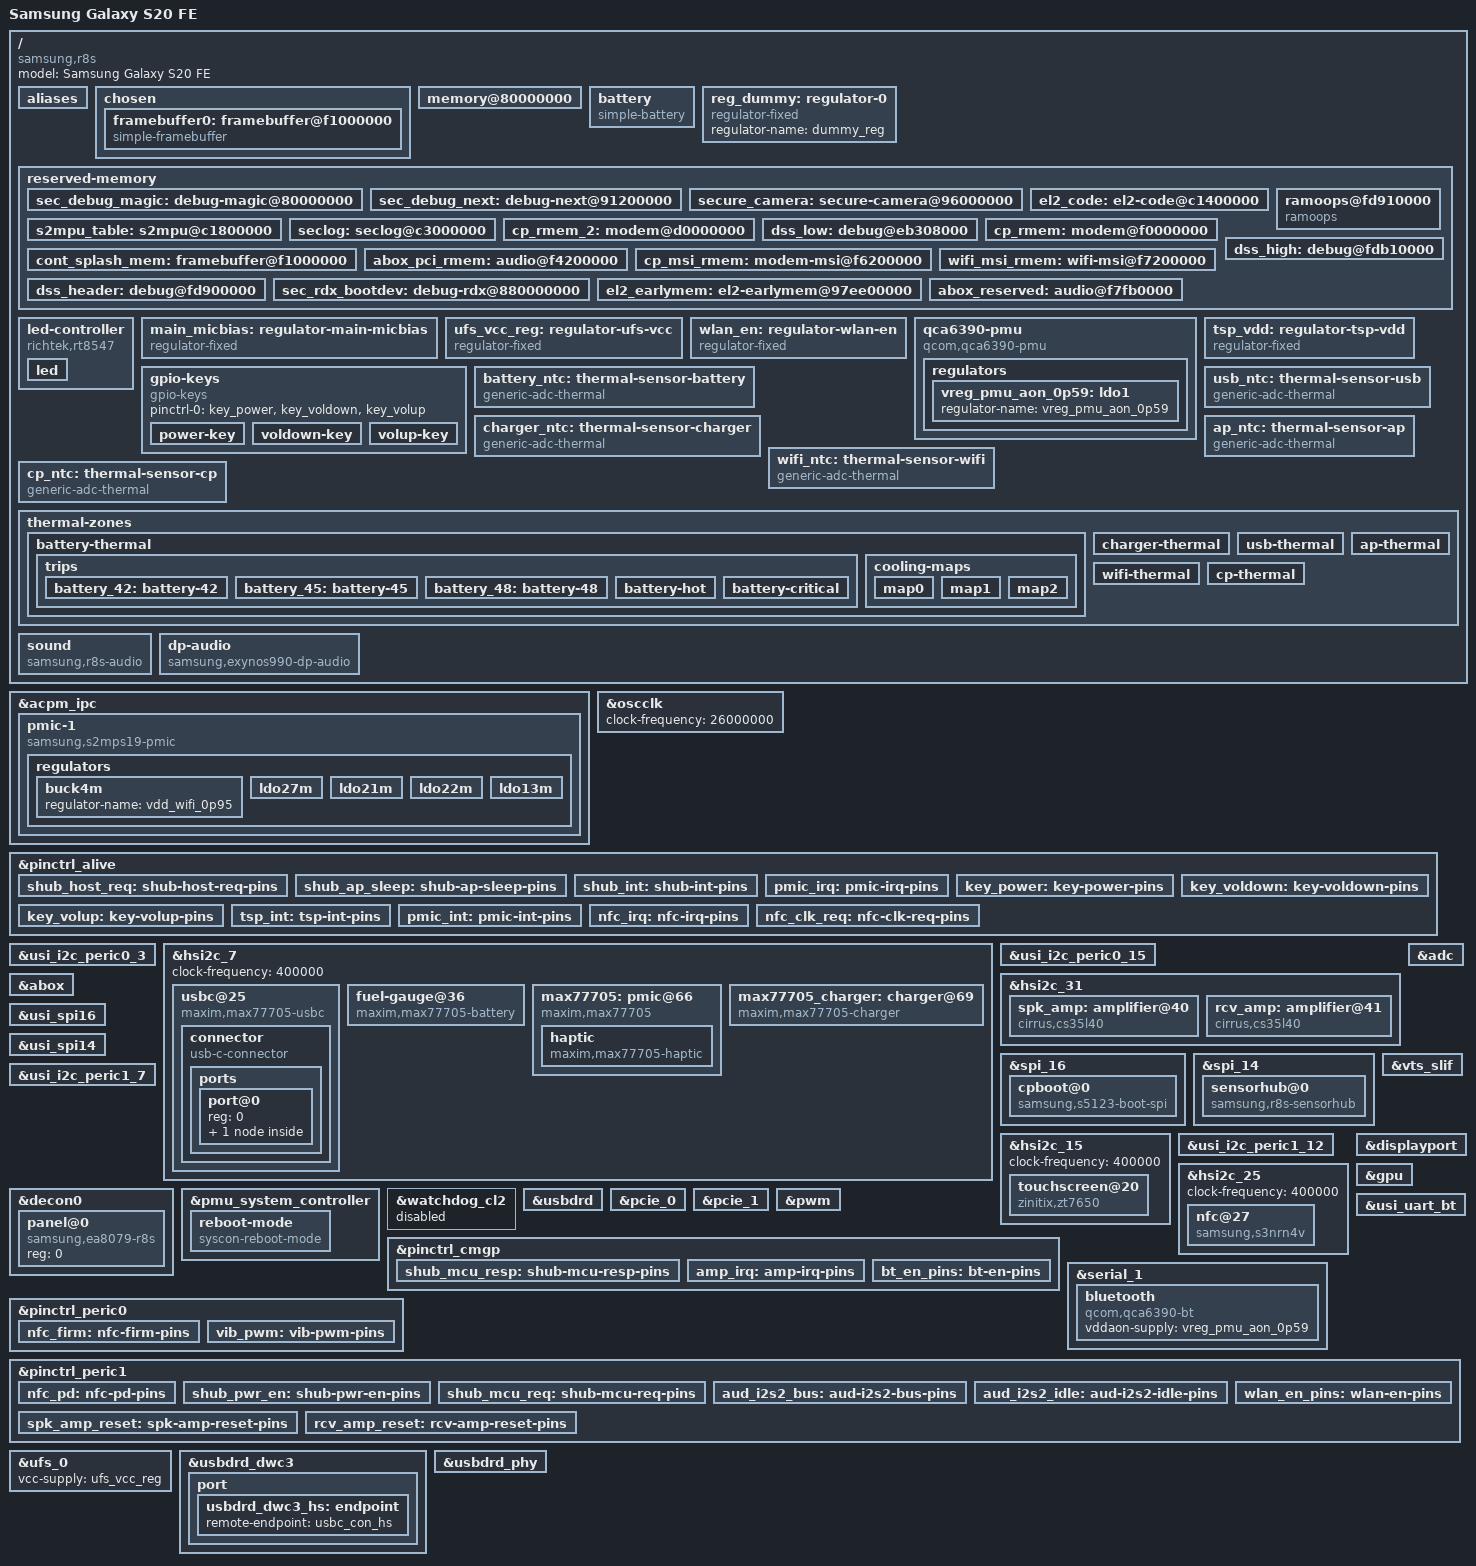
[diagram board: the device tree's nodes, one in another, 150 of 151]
// SPDX-License-Identifier: GPL-2.0 OR BSD-3-Clause
/*
 * Samsung Galaxy S20 FE (r8s/SM-G780F) device tree source
 *
 * Copyright (c) 2024, Denzeel Oliva <wachiturroxd150@gmail.com>
 */

/dts-v1/;
#include "exynos990.dtsi"
#include <dt-bindings/gpio/gpio.h>
#include <dt-bindings/leds/common.h>
#include <dt-bindings/input/input.h>
#include <dt-bindings/interrupt-controller/irq.h>
#include <dt-bindings/usb/pd.h>

/ {
	model = "Samsung Galaxy S20 FE";
	compatible = "samsung,r8s", "samsung,exynos990";

	#address-cells = <2>;
	#size-cells = <2>;

	aliases {
		/*
		 * Fixed SPI bus numbers: the modem's CP boot SPI is spi0.0 for
		 * s5123-modem (spidev), whatever else gets an SPI controller.
		 */
		spi0 = &spi_16;
		spi1 = &spi_14;
		/*
		 * Fixed I2C bus numbers, as they came up in address order before
		 * the NFC's bus: the charger stays on i2c-0 for userspace tools.
		 */
		i2c0 = &hsi2c_7;
		i2c1 = &hsi2c_31;
		i2c2 = &hsi2c_15;
		i2c3 = &hsi2c_25;
	};

	chosen {
		#address-cells = <2>;
		#size-cells = <2>;
		ranges;

		/*
		 * The shim in BOOT ignores the DTB S-Boot passes, so nothing of
		 * S-Boot's command line reaches the kernel. The clocks feeding
		 * DECON have no consumer here: keep them on.
		 */
		bootargs = "console=tty0 loglevel=7 ignore_loglevel fbcon=font:TER16x32 clk_ignore_unused pd_ignore_unused panic=5 printk.devkmsg=on s3c2410_wdt.tmr_atboot=1 s3c2410_wdt.tmr_margin=60 sysctl.kernel.panic_on_rcu_stall=1";

		framebuffer0: framebuffer@f1000000 {
			compatible = "simple-framebuffer";
			reg = <0 0xf1000000 0 (1080 * 2400 * 4)>;
			width = <1080>;
			height = <2400>;
			stride = <(1080 * 4)>;
			format = "a8r8g8b8";
		};
	};

	memory@80000000 {
		device_type = "memory";
		reg = <0x0 0x80000000 0x0 0x3ab00000>,
		      /* Memory hole */
		      <0x0 0xc1200000 0x0 0x1ee00000>,
		      /* Memory hole */
		      <0x0 0xe1900000 0x0 0x1e700000>,
		      /* Memory hole - last block: 4 GiB on the 6 GiB G780F, as
		       * S-Boot lists it (8 x 512 MiB to 0x980000000); its top
		       * 18 MiB is the hypervisor's, see el2_earlymem */
		      <0x8 0x80000000 0x1 0x00000000>;
	};

	/*
	 * 4500 mAh. Stock floats at 4.38 V (battery,chg_float_voltage); the
	 * charger driver programs voltage-max-design as its float voltage,
	 * and 4.2 V (~85-90 %) is kept on purpose: a bring-up phone lives on
	 * USB all day.
	 */
	battery: battery {
		compatible = "simple-battery";
		voltage-max-design-microvolt = <4200000>;
		charge-full-design-microamp-hours = <4500000>;
	};

	/* TODO: Remove this once PMIC is implemented */
	reg_dummy: regulator-0 {
		compatible = "regulator-fixed";
		regulator-name = "dummy_reg";
	};

	reserved-memory {
		#address-cells = <2>;
		#size-cells = <2>;
		ranges;

		/*
		 * Carve-outs below are the fixed regions S-Boot hands its own
		 * kernel (/sys/firmware/fdt of a stock-bootloader boot, G780FXXUAEVK3).
		 */

		/* sec_debug_magic page + the KASLR page S-Boot fills */
		sec_debug_magic: debug-magic@80000000 {
			reg = <0 0x80000000 0 0x2000>;
			no-map;
		};

		/* sec_debug_next=0x1000000@0x91200000 on S-Boot's command line */
		sec_debug_next: debug-next@91200000 {
			reg = <0 0x91200000 0 0x1000000>;
			no-map;
		};

		secure_camera: secure-camera@96000000 {
			reg = <0 0x96000000 0 0x3200000>;
			no-map;
		};

		/* hypervisor code: the kernel runs at EL1 under it */
		el2_code: el2-code@c1400000 {
			reg = <0 0xc1400000 0 0x200000>;
			no-map;
		};

		s2mpu_table: s2mpu@c1800000 {
			reg = <0 0xc1800000 0 0x300000>;
			no-map;
		};

		seclog: seclog@c3000000 {
			reg = <0 0xc3000000 0 0x80000>;
			no-map;
		};

		cp_rmem_2: modem@d0000000 {
			reg = <0 0xd0000000 0 0x4000000>;
			no-map;
		};

		/* dss log_pstore, log_s2d, log_arrdumppanic, camera_rmem, teegris_rmem */
		dss_low: debug@eb308000 {
			reg = <0 0xeb308000 0 0x200a000>;
			no-map;
		};

		cp_rmem: modem@f0000000 {
			reg = <0 0xf0000000 0 0x800000>;
			no-map;
		};

		cont_splash_mem: framebuffer@f1000000 {
			reg = <0 0xf1000000 0 0x13c6800>;
			no-map;
		};

		abox_pci_rmem: audio@f4200000 {
			reg = <0 0xf4200000 0 0x800000>;
			no-map;
		};

		cp_msi_rmem: modem-msi@f6200000 {
			reg = <0 0xf6200000 0 0x1000>;
			no-map;
		};

		wifi_msi_rmem: wifi-msi@f7200000 {
			reg = <0 0xf7200000 0 0x1000>;
			no-map;
		};

		/* debug-snapshot header, before the log_kernel buffer */
		dss_header: debug@fd900000 {
			reg = <0 0xfd900000 0 0x10000>;
			no-map;
		};

		/*
		 * debug-snapshot log_kernel: the stock and Lineage Recovery
		 * kernels show this buffer raw as /proc/last_kmsg on the next
		 * boot, so a console written here is readable from the recovery.
		 */
		ramoops@fd910000 {
			compatible = "ramoops";
			reg = <0 0xfd910000 0 0x200000>;
			console-size = <0x200000>;
			no-map;
		};

		/* debug-snapshot log_platform .. log_fatal, up to 4 GiB */
		dss_high: debug@fdb10000 {
			reg = <0 0xfdb10000 0 0x24f0000>;
			no-map;
		};

		sec_rdx_bootdev: debug-rdx@880000000 {
			reg = <0x8 0x80000000 0 0xad00000>;
			no-map;
		};

		/* the uH hypervisor's early memory at the top of DRAM; S-Boot
		 * reserves it without no-map, so it must never be touched */
		el2_earlymem: el2-earlymem@97ee00000 {
			reg = <0x9 0x7ee00000 0 0x1200000>;
			no-map;
		};

		abox_reserved: audio@f7fb0000 {
			reg = <0 0xf7fb0000 0 0x2a50000>;
			no-map;
		};
	};

	/* the camera flash, lit only as a torch: up to 225 mA, stock's continuous level */
	led-controller {
		compatible = "richtek,rt8547";
		enable-gpios = <&gpp4 0 GPIO_ACTIVE_HIGH>;
		ctrl-gpios = <&gpp4 4 GPIO_ACTIVE_HIGH>;

		led {
			function = LED_FUNCTION_FLASH;
			color = <LED_COLOR_ID_WHITE>;
			led-max-microamp = <225000>;
		};
	};

	/* the main microphone's 1.8 V (stock main_micbias_1p8, from buck12m) */
	main_micbias: regulator-main-micbias {
		compatible = "regulator-fixed";
		regulator-name = "main-micbias";
		regulator-min-microvolt = <1800000>;
		regulator-max-microvolt = <1800000>;
		gpio = <&gpp4 1 GPIO_ACTIVE_HIGH>;
		enable-active-high;
		startup-delay-us = <5000>;
	};

	/* UFS VCC: downstream "ufs-vcc" fixed regulator on gpg1-0 (xboot-ldo). */
	ufs_vcc_reg: regulator-ufs-vcc {
		compatible = "regulator-fixed";
		regulator-name = "ufs-vcc";
		gpio = <&gpg1 0 GPIO_ACTIVE_HIGH>;
		enable-active-high;
		regulator-boot-on;
		regulator-always-on;
	};

	/*
	 * The QCA6390's WLAN_EN (stock cnss-qca6390 wlan-en-gpio, gpb0-4) on its 0.95 V core
	 * rail (VDD_WIFI_0P95, buck4m). It keeps its level in the SoC's power-down mode, like
	 * stock's cnss_wlan_en_active.
	 */
	wlan_en: regulator-wlan-en {
		compatible = "regulator-fixed";
		regulator-name = "wlan-en";
		gpio = <&gpb0 4 GPIO_ACTIVE_HIGH>;
		enable-active-high;
		vin-supply = <&buck4m>;
		pinctrl-names = "default";
		pinctrl-0 = <&wlan_en_pins>;
		startup-delay-us = <50000>;
	};

	/*
	 * The QCA6390's own PMU, for the power sequencer hci_qca needs. It drives
	 * BT_EN (stock bluetooth gpios[0], gpm16-0) on the same 0.95 V rail as the
	 * Wi-Fi. WLAN_EN stays with wlan_en above, which the PCIe host enables.
	 * The other supplies are always-on PMIC rails (stock lists only
	 * VDD_WIFI_0P95), so they are left to dummies. The regulators child is
	 * only what the sequencer matches the Bluetooth node against.
	 */
	qca6390-pmu {
		compatible = "qcom,qca6390-pmu";
		pinctrl-names = "default";
		pinctrl-0 = <&bt_en_pins>;
		vddaon-supply = <&buck4m>;
		vddpmu-supply = <&buck4m>;
		vddrfa0p95-supply = <&buck4m>;
		bt-enable-gpios = <&gpm16 0 GPIO_ACTIVE_HIGH>;

		regulators {
			vreg_pmu_aon_0p59: ldo1 {
				regulator-name = "vreg_pmu_aon_0p59";
			};
		};
	};

	/* the touchscreen's 3.0 V: downstream "tsp_ldo_en" on gpm21-0 */
	tsp_vdd: regulator-tsp-vdd {
		compatible = "regulator-fixed";
		regulator-name = "tsp-vdd";
		regulator-min-microvolt = <3000000>;
		regulator-max-microvolt = <3000000>;
		gpio = <&gpm21 0 GPIO_ACTIVE_HIGH>;
		enable-active-high;
		/* downstream waits this long before powering the chip again */
		off-on-delay-us = <300000>;
	};

	gpio-keys {
		compatible = "gpio-keys";

		pinctrl-0 = <&key_power &key_voldown &key_volup>;
		pinctrl-names = "default";

		power-key {
			label = "Power";
			linux,code = <KEY_POWER>;
			gpios = <&gpa2 4 GPIO_ACTIVE_LOW>;
			wakeup-source;
		};

		voldown-key {
			label = "Volume Down";
			linux,code = <KEY_VOLUMEDOWN>;
			gpios = <&gpa0 4 GPIO_ACTIVE_LOW>;
		};

		volup-key {
			label = "Volume Up";
			linux,code = <KEY_VOLUMEUP>;
			gpios = <&gpa0 3 GPIO_ACTIVE_LOW>;
		};
	};
};

&acpm_ipc {
	/* the main PMIC, through the APM firmware (ACPM channel 2, speedy channel 0) */
	pmic-1 {
		compatible = "samsung,s2mps19-pmic";
		interrupts-extended = <&gpa0 1 IRQ_TYPE_LEVEL_LOW>;
		pinctrl-names = "default";
		pinctrl-0 = <&pmic_irq>;
		wakeup-source;

		regulators {
			buck4m: buck4m {
				regulator-name = "vdd_wifi_0p95";
			};

			/* the vibrator's 3.3 V (stock VDD_MOTOR_3P3) */
			ldo27m: ldo27m {
				regulator-name = "vdd-motor";
				regulator-min-microvolt = <3300000>;
				regulator-max-microvolt = <3300000>;
			};

			/* the sensor hub's 1.8 V (stock vdd_mcu_1p8), switched by its driver */
			ldo21m: ldo21m {
				regulator-name = "vdd-mcu-1p8";
				regulator-min-microvolt = <1800000>;
				regulator-max-microvolt = <1800000>;
			};

			/*
			 * NFC PVDD (stock VDD_NFC_1P8, 1.8 V fixed), also the
			 * rear light sensor's I2C supply; switched by the NFC
			 * driver, as stock's ldo_control does
			 */
			ldo22m: ldo22m {
				regulator-name = "vdd-nfc-1p8";
				regulator-min-microvolt = <1800000>;
				regulator-max-microvolt = <1800000>;
			};

			/* the sub (top) microphone's 1.8 V (stock sub_micbias_1p8) */
			ldo13m: ldo13m {
				regulator-name = "sub-micbias";
				regulator-min-microvolt = <1800000>;
				regulator-max-microvolt = <1800000>;
			};
		};
	};
};

&oscclk {
	clock-frequency = <26000000>;
};

&pinctrl_alive {
	/* the sensor hub's HOST_REQ: it has data for the AP */
	shub_host_req: shub-host-req-pins {
		samsung,pins = "gpa1-7";
		samsung,pin-function = <EXYNOS_PIN_FUNC_EINT>;
		samsung,pin-pud = <EXYNOS_PIN_PULL_DOWN>;
	};

	/* AP_SLEEP (stock "ssp-batch-wake-irq"), an AP output the hub reads */
	shub_ap_sleep: shub-ap-sleep-pins {
		samsung,pins = "gpa0-5";
		samsung,pin-function = <EXYNOS_PIN_FUNC_OUTPUT>;
		samsung,pin-pud = <EXYNOS_PIN_PULL_NONE>;
	};

	shub_int: shub-int-pins {
		samsung,pins = "gpa4-0";
		samsung,pin-function = <EXYNOS_PIN_FUNC_INPUT>;
		samsung,pin-pud = <EXYNOS_PIN_PULL_NONE>;
	};

	/* open drain: without the pull-up the line reads low and the interrupt storms */
	pmic_irq: pmic-irq-pins {
		samsung,pins = "gpa0-1";
		samsung,pin-function = <EXYNOS_PIN_FUNC_EINT>;
		samsung,pin-pud = <EXYNOS_PIN_PULL_UP>;
		samsung,pin-drv = <EXYNOS5420_PIN_DRV_LV4>;
	};

	key_power: key-power-pins {
		samsung,pins = "gpa2-4";
		samsung,pin-function = <EXYNOS_PIN_FUNC_EINT>;
		samsung,pin-pud = <EXYNOS_PIN_PULL_NONE>;
		samsung,pin-drv = <EXYNOS5420_PIN_DRV_LV1>;
	};

	key_voldown: key-voldown-pins {
		samsung,pins = "gpa0-4";
		samsung,pin-function = <EXYNOS_PIN_FUNC_EINT>;
		samsung,pin-pud = <EXYNOS_PIN_PULL_NONE>;
		samsung,pin-drv = <EXYNOS5420_PIN_DRV_LV1>;
	};

	key_volup: key-volup-pins {
		samsung,pins = "gpa0-3";
		samsung,pin-function = <EXYNOS_PIN_FUNC_EINT>;
		samsung,pin-pud = <EXYNOS_PIN_PULL_NONE>;
		samsung,pin-drv = <EXYNOS5420_PIN_DRV_LV1>;
	};

	tsp_int: tsp-int-pins {
		samsung,pins = "gpa1-0";
		samsung,pin-function = <EXYNOS_PIN_FUNC_EINT>;
		samsung,pin-pud = <EXYNOS_PIN_PULL_NONE>;
	};

	pmic_int: pmic-int-pins {
		samsung,pins = "gpa1-6";
		samsung,pin-function = <EXYNOS_PIN_FUNC_EINT>;
		samsung,pin-pud = <EXYNOS_PIN_PULL_NONE>;
	};

	/* the NFC chip's interrupt and its request for the reference clock */
	nfc_irq: nfc-irq-pins {
		samsung,pins = "gpa1-2";
		samsung,pin-function = <EXYNOS_PIN_FUNC_EINT>;
		samsung,pin-pud = <EXYNOS_PIN_PULL_DOWN>;
	};

	nfc_clk_req: nfc-clk-req-pins {
		samsung,pins = "gpa2-6";
		samsung,pin-function = <EXYNOS_PIN_FUNC_EINT>;
		samsung,pin-pud = <EXYNOS_PIN_PULL_DOWN>;
	};
};

/* MAX77705: PMIC top, charger and fuel gauge (vendor hsi2c7) */
&usi_i2c_peric0_3 {
	status = "okay";
};

&hsi2c_7 {
	clock-frequency = <400000>;
	status = "okay";

	/*
	 * The MAX77705's USB-C/PD block: sets the charger's input and charge
	 * current from the source's PD contract, Rp current or BC1.2 type.
	 * Sink limits as stock (pd_charging_charge_power, max input 9 V).
	 */
	usbc@25 {
		compatible = "maxim,max77705-usbc";
		reg = <0x25>;
		interrupt-parent = <&max77705>;
		interrupts = <3>;

		connector {
			compatible = "usb-c-connector";
			power-role = "dual";
			data-role = "dual";
			try-power-role = "sink";
			op-sink-microwatt = <15000000>;
			sink-pdos = <PDO_FIXED(5000, 3000, PDO_FIXED_USB_COMM)
				     PDO_FIXED(9000, 1670, 0)>;

			ports {
				#address-cells = <1>;
				#size-cells = <0>;

				/* USB 2.0: the data role goes to the controller */
				port@0 {
					reg = <0>;

					usbc_con_hs: endpoint {
						remote-endpoint = <&usbdrd_dwc3_hs>;
					};
				};
			};
		};
	};

	fuel-gauge@36 {
		compatible = "maxim,max77705-battery";
		reg = <0x36>;
		power-supplies = <&max77705_charger>;
		/* fuelgauge,fg_resistor = 2: 5 mOhm, as on the S10e */
		shunt-resistor-micro-ohms = <5000>;
		interrupt-parent = <&max77705>;
		interrupts = <2>;
	};

	max77705: pmic@66 {
		compatible = "maxim,max77705";
		reg = <0x66>;
		interrupts-extended = <&gpa1 6 IRQ_TYPE_LEVEL_LOW>;
		interrupt-controller;
		#interrupt-cells = <1>;
		pinctrl-0 = <&pmic_int>;
		pinctrl-names = "default";

		/*
		 * The linear vibrator, driven at PWM / 128. Stock's period is
		 * 37.65 us (207.5 Hz), but the boot loader leaves the PWM
		 * ticking at 1 MHz: 38 us (205.6 Hz) is the nearest step and
		 * measured strongest (37 us: 211 Hz, -6 %; 36 us: 217 Hz, -35 %).
		 */
		haptic {
			compatible = "maxim,max77705-haptic";
			haptic-supply = <&ldo27m>;
			pwms = <&pwm 1 38000 0>;
			/* this motor barely moves below ~75 % duty or in under 15 ms */
			maxim,min-magnitude-percent = <50>;
			maxim,min-on-ms = <15>;
		};
	};

	max77705_charger: charger@69 {
		compatible = "maxim,max77705-charger";
		reg = <0x69>;
		monitored-battery = <&battery>;
		/* Qi at 5 V, 5 W: the owner's choice (stock's BPP limit is 1.1 A) */
		maxim,wcin-current-limit-microamp = <1000000>;
		interrupt-parent = <&max77705>;
		interrupts = <0>;
	};
};

/*
 * The speaker amps (vendor hsi2c31): two CS35L40s on one TDM bus, bottom
 * loudspeaker @40 ("cs35l40-bot", right channel) and earpiece @41
 * ("cs35l40-rcv"). VA is an always-on 1.8 V rail of the sub PMIC and VP is
 * the battery, so both stay with dummies. Boost: stock sets only the 4.1 A
 * peak; inductor and cap are the chip-reset defaults, as on the S10e.
 */
&usi_i2c_peric0_15 {
	status = "okay";
};

&hsi2c_31 {
	clock-frequency = <400000>;
	pinctrl-names = "default";
	pinctrl-0 = <&hsi2c31_bus &amp_irq>;
	status = "okay";

	spk_amp: amplifier@40 {
		compatible = "cirrus,cs35l40";
		reg = <0x40>;
		#sound-dai-cells = <1>;
		sound-name-prefix = "SPK";

		pinctrl-names = "default";
		pinctrl-0 = <&spk_amp_reset>;
		reset-gpios = <&gpb2 5 GPIO_ACTIVE_HIGH>;
		interrupts-extended = <&gpm24 0 IRQ_TYPE_LEVEL_LOW>;

		cirrus,boost-type = <0>;
		cirrus,boost-peak-milliamp = <4100>;
		cirrus,boost-ind-nanohenry = <1000>;
		cirrus,boost-cap-microfarad = <15>;
		cirrus,asp-sdout-hiz = <3>;
	};

	rcv_amp: amplifier@41 {
		compatible = "cirrus,cs35l40";
		reg = <0x41>;
		#sound-dai-cells = <1>;
		sound-name-prefix = "RCV";

		pinctrl-names = "default";
		pinctrl-0 = <&rcv_amp_reset>;
		reset-gpios = <&gpb2 4 GPIO_ACTIVE_HIGH>;
		interrupts-extended = <&gpm24 0 IRQ_TYPE_LEVEL_LOW>;

		cirrus,boost-type = <0>;
		cirrus,boost-peak-milliamp = <4100>;
		cirrus,boost-ind-nanohenry = <1000>;
		cirrus,boost-cap-microfarad = <15>;
		cirrus,asp-sdout-hiz = <3>;
	};
};

/*
 * The NTC thermistors stock reads on the general-purpose ADC, with stock's
 * tables (battery,temp_table, chg_temp_table, usb_temp_table). The ADC has no
 * vdd-supply on purpose: without one it reports no IIO scale, and the tables
 * apply to its raw 12-bit counts as they do in the stock kernel.
 */
&adc {
	status = "okay";
};

/ {
	battery_ntc: thermal-sensor-battery {
		compatible = "generic-adc-thermal";
		#thermal-sensor-cells = <0>;
		io-channels = <&adc 4>;
		io-channel-names = "sensor-channel";
		temperature-lookup-table = <
			(-20000) 3694 (-15000) 3580 (-10000) 3451 (-5000) 3305
			(0) 3125 (5000) 2926 (10000) 2708 (15000) 2483
			(20000) 2244 (25000) 2007 (30000) 1821 (35000) 1616
			(40000) 1411 (45000) 1242 (50000) 1072 (55000) 937
			(60000) 802 (65000) 649 (70000) 558 (75000) 482
			(80000) 417 (85000) 387 (90000) 311>;
	};

	/* next to the MAX77705 charger */
	charger_ntc: thermal-sensor-charger {
		compatible = "generic-adc-thermal";
		#thermal-sensor-cells = <0>;
		io-channels = <&adc 3>;
		io-channel-names = "sensor-channel";
		temperature-lookup-table = <
			(-20000) 3617 (-15000) 3512 (-10000) 3381 (-5000) 3228
			(0) 3047 (5000) 2850 (10000) 2634 (15000) 2410
			(20000) 2177 (25000) 1937 (30000) 1757 (35000) 1555
			(40000) 1353 (45000) 1185 (50000) 1018 (55000) 884
			(60000) 751 (65000) 600 (70000) 499 (75000) 432
			(80000) 366 (85000) 341 (90000) 221>;
	};

	/* at the USB-C receptacle */
	usb_ntc: thermal-sensor-usb {
		compatible = "generic-adc-thermal";
		#thermal-sensor-cells = <0>;
		io-channels = <&adc 1>;
		io-channel-names = "sensor-channel";
		temperature-lookup-table = <
			(-20000) 3653 (-15000) 3545 (-10000) 3421 (-5000) 3274
			(0) 3101 (5000) 2910 (10000) 2701 (15000) 2480
			(20000) 2247 (25000) 2012 (30000) 1830 (35000) 1626
			(40000) 1423 (45000) 1251 (50000) 1079 (55000) 941
			(60000) 803 (65000) 646 (70000) 552 (75000) 472
			(80000) 402 (85000) 370 (90000) 268>;
	};

	/*
	 * Board thermistors with stock's tables: by the AP, by the Wi-Fi and
	 * by the modem. Read only, as zones without trips.
	 */
	ap_ntc: thermal-sensor-ap {
		compatible = "generic-adc-thermal";
		#thermal-sensor-cells = <0>;
		io-channels = <&adc 0>;
		io-channel-names = "sensor-channel";
		temperature-lookup-table = <
			(-20000) 3670 (-15000) 3555 (-10000) 3433 (-5000) 3279
			(0) 3087 (5000) 2888 (10000) 2656 (15000) 2416
			(20000) 2179 (25000) 1955 (30000) 1725 (35000) 1504
			(40000) 1300 (45000) 1099 (50000) 949 (55000) 806
			(60000) 682 (65000) 575 (70000) 481 (75000) 403
			(80000) 337 (85000) 280 (90000) 217>;
	};

	wifi_ntc: thermal-sensor-wifi {
		compatible = "generic-adc-thermal";
		#thermal-sensor-cells = <0>;
		io-channels = <&adc 2>;
		io-channel-names = "sensor-channel";
		temperature-lookup-table = <
			(-20000) 3629 (-15000) 3544 (-10000) 3403 (-5000) 3256
			(0) 3083 (5000) 2893 (10000) 2666 (15000) 2446
			(20000) 2211 (25000) 1978 (30000) 1753 (35000) 1535
			(40000) 1333 (45000) 1146 (50000) 982 (55000) 839
			(60000) 714 (65000) 604 (70000) 510 (75000) 429
			(80000) 359 (85000) 302 (90000) 239>;
	};

	cp_ntc: thermal-sensor-cp {
		compatible = "generic-adc-thermal";
		#thermal-sensor-cells = <0>;
		io-channels = <&adc 5>;
		io-channel-names = "sensor-channel";
		temperature-lookup-table = <
			(-20000) 3694 (-15000) 3587 (-10000) 3451 (-5000) 3298
			(0) 3113 (5000) 2907 (10000) 2675 (15000) 2447
			(20000) 2208 (25000) 1971 (30000) 1741 (35000) 1521
			(40000) 1316 (45000) 1122 (50000) 961 (55000) 819
			(60000) 694 (65000) 587 (70000) 494 (75000) 414
			(80000) 347 (85000) 291 (90000) 228>;
	};

	/*
	 * battery-thermal is read by max77705-usbc and max77705-charger for
	 * their charge limits. It also slows the SoC down on a hot battery,
	 * which nothing else does while no input is connected: from 42 C the
	 * big and middle cores and the GPU in rungs, at 48 C all of them down
	 * to their lowest levels. 55 C is "hot" (a thermal event for
	 * userspace), 60 C shuts down.
	 */
	thermal-zones {
		battery-thermal {
			polling-delay-passive = <2000>;
			polling-delay = <5000>;
			thermal-sensors = <&battery_ntc>;

			trips {
				battery_42: battery-42 {
					temperature = <42000>;
					hysteresis = <1000>;
					type = "passive";
				};

				battery_45: battery-45 {
					temperature = <45000>;
					hysteresis = <1000>;
					type = "passive";
				};

				battery_48: battery-48 {
					temperature = <48000>;
					hysteresis = <1000>;
					type = "passive";
				};

				battery-hot {
					temperature = <55000>;
					hysteresis = <1000>;
					type = "hot";
				};

				battery-critical {
					temperature = <60000>;
					hysteresis = <0>;
					type = "critical";
				};
			};

			cooling-maps {
				map0 {
					trip = <&battery_42>;
					cooling-device = <&cpu6 4 8>, <&cpu7 4 8>,
							 <&cpu4 2 6>, <&cpu5 2 6>,
							 <&gpu 1 2>;
				};

				map1 {
					trip = <&battery_45>;
					cooling-device = <&cpu6 8 14>, <&cpu7 8 14>,
							 <&cpu4 6 11>, <&cpu5 6 11>,
							 <&gpu 2 4>;
				};

				map2 {
					trip = <&battery_48>;
					cooling-device = <&cpu6 14 21>, <&cpu7 14 21>,
							 <&cpu4 11 18>, <&cpu5 11 18>,
							 <&cpu0 0 13>, <&cpu1 0 13>,
							 <&cpu2 0 13>, <&cpu3 0 13>,
							 <&gpu 4 7>;
				};
			};
		};

		charger-thermal {
			polling-delay-passive = <0>;
			polling-delay = <0>;
			thermal-sensors = <&charger_ntc>;
		};

		usb-thermal {
			polling-delay-passive = <0>;
			polling-delay = <0>;
			thermal-sensors = <&usb_ntc>;
		};

		ap-thermal {
			polling-delay-passive = <0>;
			polling-delay = <0>;
			thermal-sensors = <&ap_ntc>;
		};

		wifi-thermal {
			polling-delay-passive = <0>;
			polling-delay = <0>;
			thermal-sensors = <&wifi_ntc>;
		};

		cp-thermal {
			polling-delay-passive = <0>;
			polling-delay = <0>;
			thermal-sensors = <&cp_ntc>;
		};
	};
};

&abox {
	/* the firmware DRAM is the last 42 MiB of abox_reserved (0xf8000000) */
	memory-region = <&abox_reserved>, <&abox_pci_rmem>;
	memory-region-names = "fw", "pci";
	/* "pci": stock selects aud-i2s4-pci for its voice path; ours on request */
	pinctrl-names = "active", "idle", "pci";
	pinctrl-0 = <&aud_i2s2_bus>;
	pinctrl-1 = <&aud_i2s2_idle>;
	pinctrl-2 = <&aud_i2s2_bus>, <&aud_i2s4_pci>;
	status = "okay";
};

/ {
	sound {
		compatible = "samsung,r8s-audio";
		samsung,audio-cpu = <&abox>;
		/* TDM slot order: earpiece amp on slot 0, loudspeaker amp on slot 1 */
		samsung,speaker-amps = <&rcv_amp>, <&spk_amp>;
		samsung,mic-codec = <&vts_slif>;
	};

	/* sound over the USB-C DisplayPort: DP0's audio FIFO on PDMA0 request 28 (stock dp_dma@0) */
	dp-audio {
		compatible = "samsung,exynos990-dp-audio";
		samsung,dp = <&displayport>;
		dmas = <&pdma0 28>;
		dma-names = "tx";
	};
};

/* the PDM mics: line 0 (gpv0-0 clock, gpv0-3 data) and line 1 (gpv0-1, gpv0-4) */
&usi_spi16 {
	status = "okay";
};

/*
 * The S5123 modem's boot SPI: its ROM takes the CP bootloader here, TX only,
 * at about stock's 2.15 MHz. SCK is the IP clock / 4, and the USI16 divider
 * can't get there from the 400 MHz PERIC1 IP clock: 2.17 MHz lands on
 * OSCCLK / 3, which the clock framework picks when the first transfer sets
 * the rate (with the clock running; switching the mux while it is gated
 * left the bus without a clock and the boot hard-locked in the SPI probe).
 */
&spi_16 {
	status = "okay";

	cpboot@0 {
		compatible = "samsung,s5123-boot-spi";
		reg = <0>;
		spi-max-frequency = <2166667>;
	};
};

/*
 * The BCM4775 B1 sensor hub + GNSS (stock "ssp,BCM4773"), on USI14's SPI like
 * the S10e's B0 on its spi17: same driver, its own RAM patch. SPI mode 3 at
 * 25 MHz, chip select as a GPIO so it stays down through a whole transfer.
 */
&usi_spi14 {
	status = "okay";
};

&spi_14 {
	pinctrl-0 = <&spi14_bus &spi14_cs>;
	cs-gpios = <&gpp3 7 GPIO_ACTIVE_LOW>;
	status = "okay";

	sensorhub@0 {
		compatible = "samsung,r8s-sensorhub", "brcm,bcm4775-shub";
		reg = <0>;
		spi-max-frequency = <25000000>;
		spi-cpol;
		spi-cpha;

		pinctrl-names = "default";
		pinctrl-0 = <&shub_host_req &shub_ap_sleep &shub_int
			     &shub_pwr_en &shub_mcu_req &shub_mcu_resp>;
		vdd-supply = <&ldo21m>;
		pwr-en-gpios = <&gpp6 3 GPIO_ACTIVE_HIGH>;
		mcu-req-gpios = <&gpb0 5 GPIO_ACTIVE_HIGH>;
		mcu-resp-gpios = <&gpm19 0 GPIO_ACTIVE_HIGH>;
		host-req-gpios = <&gpa1 7 GPIO_ACTIVE_HIGH>;
		ap-sleep-gpios = <&gpa0 5 GPIO_ACTIVE_HIGH>;
	};
};

&vts_slif {
	pinctrl-names = "default", "idle";
	pinctrl-0 = <&dmic_bus_clk>, <&dmic_pdm>, <&dmic_bus_clk1>, <&dmic_pdm1_bus>;
	pinctrl-1 = <&dmic_bus_clk_idle>, <&dmic_pdm_idle>,
		    <&dmic_bus_clk1_idle>, <&dmic_pdm1_idle>;
	mic0-supply = <&main_micbias>;
	mic1-supply = <&ldo13m>;
	status = "okay";
};

/* touchscreen bus (vendor hsi2c15): Zinitix @0x20 or STM FTS @0x49 */
&usi_i2c_peric1_7 {
	status = "okay";
};

&hsi2c_15 {
	clock-frequency = <400000>;
	status = "okay";

	/* some r8s units carry an STM FTS5CU56A at 0x49 instead */
	touchscreen@20 {
		compatible = "zinitix,zt7650";
		reg = <0x20>;
		interrupt-parent = <&gpa1>;
		interrupts = <0 IRQ_TYPE_LEVEL_LOW>;
		pinctrl-names = "default";
		pinctrl-0 = <&tsp_int>;
		vdd-supply = <&tsp_vdd>;
		touchscreen-size-x = <1080>;
		touchscreen-size-y = <2400>;
	};
};

/*
 * NFC (vendor hsi2c25, USI12's I2C channel): Samsung S3NRN4V. Its 1.8 V
 * PVDD is the S2MPS19's LDO22M, which also powers this bus's pull-ups and
 * the rear light sensor; the driver switches it with the chip. The
 * reference clock is the PMU's CLKOUT1 (26 MHz TCXO), gated on CLK_REQ.
 */
&usi_i2c_peric1_12 {
	status = "okay";
};

&hsi2c_25 {
	clock-frequency = <400000>;
	status = "okay";

	nfc@27 {
		compatible = "samsung,s3nrn4v";
		reg = <0x27>;
		interrupt-parent = <&gpa1>;
		interrupts = <2 IRQ_TYPE_EDGE_RISING>;
		en-gpios = <&gpp6 0 GPIO_ACTIVE_HIGH>;
		wake-gpios = <&gpp3 0 GPIO_ACTIVE_HIGH>;
		clk-req-gpios = <&gpa2 6 GPIO_ACTIVE_HIGH>;
		clocks = <&pmu_system_controller 0>;
		pvdd-supply = <&ldo22m>;
		pinctrl-names = "default";
		pinctrl-0 = <&nfc_irq &nfc_clk_req &nfc_pd &nfc_firm>;
	};
};

/* S-Boot's running pipeline: page flips, and the EA8079 it lit as a DSI device */
&decon0 {
	status = "okay";

	panel@0 {
		compatible = "samsung,ea8079-r8s";
		reg = <0>;
	};
};

/*
 * DisplayPort over the USB-C port (alt mode, pin D, entered by usbc@25):
 * gpm26-0 reads the plug's orientation, gpp6-1 selects which SBU pin carries
 * AUX_P and gpp6-2 enables the SBU/AUX switch (low = on).
 */
&displayport {
	orientation-gpios = <&gpm26 0 GPIO_ACTIVE_HIGH>;
	sbu-sel-gpios = <&gpp6 1 GPIO_ACTIVE_HIGH>;
	aux-oe-gpios = <&gpp6 2 GPIO_ACTIVE_HIGH>;
	status = "okay";
};

&gpu {
	status = "okay";
};

&pmu_system_controller {
	/*
	 * S-Boot's reboot reason, PMU INFORM3 (downstream sec_reboot.c):
	 * 0x12345600 | 0 normal, 1 download, 4 recovery, 0xd bootloader.
	 */
	reboot-mode {
		compatible = "syscon-reboot-mode";
		offset = <0x80c>;
		mode-normal = <0x12345600>;
		mode-download = <0x12345601>;
		mode-recovery = <0x12345604>;
		mode-bootloader = <0x1234560d>;
	};
};

/*
 * cluster0's watchdog is the one S-Boot sets up and the U-Boot shim arms;
 * cluster2's would only be a second /dev/watchdog nobody feeds.
 */
&watchdog_cl2 {
	status = "disabled";
};

&usbdrd {
	status = "okay";
	vdd10-supply = <&reg_dummy>;
	vdd33-supply = <&reg_dummy>;
};

&pcie_0 {
	reset-gpios = <&gpf0 1 GPIO_ACTIVE_LOW>;
	vpcie-supply = <&wlan_en>;
	/* stock keeps the Wi-Fi's DMA memory below 4 GB (cnss wifi_region alloc-ranges) */
	dma-ranges = <0x02000000 0x0 0x0 0x0 0x1 0x0>;
	/* EL2 S2MPU "hsi1" (index 24 of the stock instance list), VID of this master */
	samsung,s2mpu = <24 1>;
	status = "okay";
};

/*
 * The S5123 modem's link. Shared memory at the addresses its firmware
 * expects; EL2 S2MPU "hsi2" (index 25 of the stock instance list) opened
 * for those regions only, for VID 0: the CP's DMA comes in as VID 0.
 */
&pcie_1 {
	reset-gpios = <&gpf3 1 GPIO_ACTIVE_LOW>;
	/* abox-pci: the call's voice, which the modem writes and ABOX reads */
	memory-region = <&cp_rmem>, <&cp_rmem_2>, <&cp_msi_rmem>, <&abox_pci_rmem>;
	memory-region-names = "ipc", "pktproc", "msi", "abox-pci";
	samsung,s2mpu = <25 0>;
	/* the VTS mailbox: the modem rings ABOX through it (stock abox-pci) */
	samsung,s2mpu-mmio = <0x155a0000 0x1000>;
	status = "okay";
};

&pwm {
	samsung,pwm-outputs = <1>;
	pinctrl-0 = <&vib_pwm>;
	pinctrl-names = "default";
	status = "okay";
};

&pinctrl_cmgp {
	shub_mcu_resp: shub-mcu-resp-pins {
		samsung,pins = "gpm19-0";
		samsung,pin-function = <EXYNOS_PIN_FUNC_INPUT>;
		samsung,pin-pud = <EXYNOS_PIN_PULL_NONE>;
	};

	/* both amps' INTB, shared (stock spk-amp-int) */
	amp_irq: amp-irq-pins {
		samsung,pins = "gpm24-0";
		samsung,pin-function = <EXYNOS_PIN_FUNC_EINT>;
		samsung,pin-pud = <EXYNOS_PIN_PULL_NONE>;
	};

	bt_en_pins: bt-en-pins {
		samsung,pins = "gpm16-0";
		samsung,pin-function = <EXYNOS_PIN_FUNC_OUTPUT>;
		samsung,pin-pud = <EXYNOS_PIN_PULL_NONE>;
		samsung,pin-drv = <EXYNOS5420_PIN_DRV_LV3>;
		samsung,pin-con-pdn = <EXYNOS_PIN_PDN_PREV>;
		samsung,pin-pud-pdn = <EXYNOS_PIN_PULL_NONE>;
	};
};

&serial_1 {
	status = "okay";

	bluetooth {
		compatible = "qcom,qca6390-bt";
		vddaon-supply = <&vreg_pmu_aon_0p59>;
	};
};

&usi_uart_bt {
	status = "okay";
};

&pinctrl_peric0 {
	/*
	 * The NFC chip's FIRM (download mode / wake). The driver makes it an
	 * output (low); only pull and drive here, as for the power-down below.
	 */
	nfc_firm: nfc-firm-pins {
		samsung,pins = "gpp3-0";
		samsung,pin-pud = <EXYNOS_PIN_PULL_NONE>;
		samsung,pin-drv = <EXYNOS5420_PIN_DRV_LV3>;
	};

	/* TOUT1, the vibrator's PWM */
	vib_pwm: vib-pwm-pins {
		samsung,pins = "gpp4-5";
		samsung,pin-function = <EXYNOS_PIN_FUNC_2>;
		samsung,pin-pud = <EXYNOS_PIN_PULL_DOWN>;
		samsung,pin-drv = <EXYNOS5420_PIN_DRV_LV1>;
	};
};

&pinctrl_peric1 {
	/*
	 * The NFC chip's power-down (stock nfc_pd, "VEN"): high is off. The
	 * driver drives it high at once; a function here would drive it low
	 * (the chip on) first.
	 */
	nfc_pd: nfc-pd-pins {
		samsung,pins = "gpp6-0";
		samsung,pin-pud = <EXYNOS_PIN_PULL_NONE>;
		samsung,pin-drv = <EXYNOS5420_PIN_DRV_LV3>;
	};

	/* the sensor hub + GNSS chip's power (stock "ssp-gps-pwr-en") */
	shub_pwr_en: shub-pwr-en-pins {
		samsung,pins = "gpp6-3";
		samsung,pin-function = <EXYNOS_PIN_FUNC_OUTPUT>;
		samsung,pin-pud = <EXYNOS_PIN_PULL_DOWN>;
	};

	shub_mcu_req: shub-mcu-req-pins {
		samsung,pins = "gpb0-5";
		samsung,pin-function = <EXYNOS_PIN_FUNC_OUTPUT>;
		samsung,pin-pud = <EXYNOS_PIN_PULL_NONE>;
	};

	/* ABOX UAIF2, the amp TDM bus (stock aud-i2s2-bus / -idle) */
	aud_i2s2_bus: aud-i2s2-bus-pins {
		samsung,pins = "gpb1-0", "gpb1-1", "gpb1-2", "gpb1-3";
		samsung,pin-function = <EXYNOS_PIN_FUNC_2>;
		samsung,pin-pud = <EXYNOS_PIN_PULL_NONE>;
	};

	aud_i2s2_idle: aud-i2s2-idle-pins {
		samsung,pins = "gpb1-0", "gpb1-1", "gpb1-2", "gpb1-3";
		samsung,pin-function = <EXYNOS_PIN_FUNC_INPUT>;
		samsung,pin-pud = <EXYNOS_PIN_PULL_DOWN>;
	};

	/* amp resets: held low (in reset) through the SoC's power-down mode */
	spk_amp_reset: spk-amp-reset-pins {
		samsung,pins = "gpb2-5";
		samsung,pin-function = <EXYNOS_PIN_FUNC_OUTPUT>;
		samsung,pin-pud = <EXYNOS_PIN_PULL_NONE>;
		samsung,pin-con-pdn = <EXYNOS_PIN_PDN_PREV>;
		samsung,pin-pud-pdn = <EXYNOS_PIN_PULL_NONE>;
	};

	rcv_amp_reset: rcv-amp-reset-pins {
		samsung,pins = "gpb2-4";
		samsung,pin-function = <EXYNOS_PIN_FUNC_OUTPUT>;
		samsung,pin-pud = <EXYNOS_PIN_PULL_NONE>;
		samsung,pin-con-pdn = <EXYNOS_PIN_PDN_PREV>;
		samsung,pin-pud-pdn = <EXYNOS_PIN_PULL_NONE>;
	};

	wlan_en_pins: wlan-en-pins {
		samsung,pins = "gpb0-4";
		samsung,pin-function = <EXYNOS_PIN_FUNC_OUTPUT>;
		samsung,pin-pud = <EXYNOS_PIN_PULL_UP>;
		samsung,pin-drv = <EXYNOS5420_PIN_DRV_LV4>;
		samsung,pin-con-pdn = <EXYNOS_PIN_PDN_PREV>;
		samsung,pin-pud-pdn = <EXYNOS_PIN_PULL_NONE>;
	};
};

&ufs_0 {
	vcc-supply = <&ufs_vcc_reg>;
};

/*
 * Host or device as usbc@25's firmware settles the data role (host behind a
 * hub or dock that made us the DFP), a device when nothing says otherwise.
 * The core's ref clock is HSI0's 40 MHz (without the period dwc3 keeps the
 * 24 MHz reset values in GUCTL REFCLKPER and GFLADJ); the UTMI+ PHY is 8 bits
 * wide, and phy_type programs PHYIF and USBTRDTIM to match (the reset value
 * read 8 bits with the 16-bit turnaround, 9).
 */
&usbdrd_dwc3 {
	dr_mode = "otg";
	usb-role-switch;
	role-switch-default-mode = "peripheral";
	maximum-speed = "high-speed";
	phy_type = "utmi";
	snps,ref-clock-period-ns = <25>;

	port {
		usbdrd_dwc3_hs: endpoint {
			remote-endpoint = <&usbc_con_hs>;
		};
	};
};

&usbdrd_phy {
	status = "okay";
};
